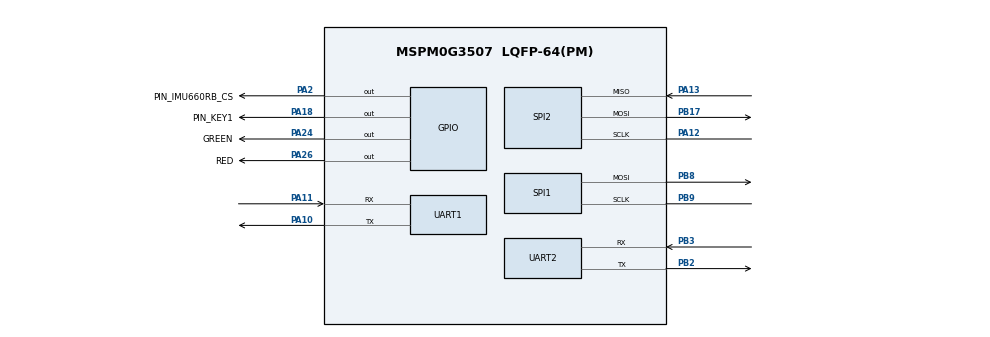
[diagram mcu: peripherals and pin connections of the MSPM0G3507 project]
/**
 * These arguments were used when this file was generated. They will be automatically applied on subsequent loads
 * via the GUI or CLI. Run CLI with '--help' for additional information on how to override these arguments.
 * @cliArgs --device "MSPM0G350X" --part "Default" --package "LQFP-64(PM)" --product "mspm0_sdk@2.02.00.05"
 * @v2CliArgs --device "MSPM0G3507" --package "LQFP-64(PM)" --product "mspm0_sdk@2.02.00.05"
 * @versions {"tool":"1.21.1+3772"}
 */

/**
 * Import the modules used in this configuration.
 */
const GPIO   = scripting.addModule("/ti/driverlib/GPIO", {}, false);
const GPIO1  = GPIO.addInstance();
const GPIO2  = GPIO.addInstance();
const GPIO3  = GPIO.addInstance();
const GPIO4  = GPIO.addInstance();
const I2C    = scripting.addModule("/ti/driverlib/I2C", {}, false);
const I2C1   = I2C.addInstance();
const SPI    = scripting.addModule("/ti/driverlib/SPI", {}, false);
const SPI1   = SPI.addInstance();
const SPI2   = SPI.addInstance();
const SYSCTL = scripting.addModule("/ti/driverlib/SYSCTL");
const UART   = scripting.addModule("/ti/driverlib/UART", {}, false);
const UART1  = UART.addInstance();
const UART2  = UART.addInstance();

/**
 * Write custom configuration values to the imported modules.
 */
const gate7  = system.clockTree["MFCLKGATE"];
gate7.enable = true;

GPIO1.$name                              = "LED1";
GPIO1.associatedPins.create(2);
GPIO1.associatedPins[0].internalResistor = "PULL_DOWN";
GPIO1.associatedPins[0].$name            = "RED";
GPIO1.associatedPins[0].assignedPin      = "26";
GPIO1.associatedPins[0].pin.$assign      = "PA26";
GPIO1.associatedPins[1].$name            = "GREEN";
GPIO1.associatedPins[1].pin.$assign      = "PA24";

const Board = scripting.addModule("/ti/driverlib/Board", {}, false);

GPIO2.$name                          = "SPI_LCD1";
GPIO2.associatedPins.create(4);
GPIO2.associatedPins[0].$name        = "RES";
GPIO2.associatedPins[0].assignedPort = "PORTB";
GPIO2.associatedPins[0].assignedPin  = "10";
GPIO2.associatedPins[1].$name        = "DC";
GPIO2.associatedPins[1].assignedPin  = "11";
GPIO2.associatedPins[1].assignedPort = "PORTB";
GPIO2.associatedPins[2].$name        = "CS";
GPIO2.associatedPins[2].assignedPort = "PORTB";
GPIO2.associatedPins[2].assignedPin  = "14";
GPIO2.associatedPins[3].$name        = "BLK";
GPIO2.associatedPins[3].assignedPort = "PORTB";
GPIO2.associatedPins[3].assignedPin  = "26";

GPIO3.$name                               = "GPIO_IMU660RB";
GPIO3.associatedPins.create(2);
GPIO3.associatedPins[0].$name             = "PIN_IMU660RB_CS";
GPIO3.associatedPins[0].pin.$assign       = "PA2";
GPIO3.associatedPins[1].$name             = "PIN_IMU660RB_INT1";
GPIO3.associatedPins[1].direction         = "INPUT";
GPIO3.associatedPins[1].interruptEn       = true;
GPIO3.associatedPins[1].interruptPriority = "3";
GPIO3.associatedPins[1].polarity          = "RISE";

GPIO4.$name                         = "GPIO_KEY";
GPIO4.associatedPins[0].$name       = "PIN_KEY1";
GPIO4.associatedPins[0].pin.$assign = "PA18";

I2C1.basicEnableController             = true;
I2C1.basicControllerStandardBusSpeed   = "Fast";
I2C1.$name                             = "I2C_OLED";
I2C1.sdaPinConfig.hideOutputInversion  = scripting.forceWrite(false);
I2C1.sdaPinConfig.onlyInternalResistor = scripting.forceWrite(false);
I2C1.sdaPinConfig.passedPeripheralType = scripting.forceWrite("Digital");
I2C1.sdaPinConfig.$name                = "ti_driverlib_gpio_GPIOPinGeneric2";
I2C1.sclPinConfig.hideOutputInversion  = scripting.forceWrite(false);
I2C1.sclPinConfig.onlyInternalResistor = scripting.forceWrite(false);
I2C1.sclPinConfig.passedPeripheralType = scripting.forceWrite("Digital");
I2C1.sclPinConfig.$name                = "ti_driverlib_gpio_GPIOPinGeneric3";

SPI1.$name                              = "SPI_LCD";
SPI1.peripheral.$assign                 = "SPI1";
SPI1.peripheral.sclkPin.$assign         = "PB9";
SPI1.peripheral.mosiPin.$assign         = "PB8";
SPI1.sclkPinConfig.direction            = scripting.forceWrite("OUTPUT");
SPI1.sclkPinConfig.onlyInternalResistor = scripting.forceWrite(false);
SPI1.sclkPinConfig.passedPeripheralType = scripting.forceWrite("Digital");
SPI1.sclkPinConfig.$name                = "ti_driverlib_gpio_GPIOPinGeneric8";
SPI1.mosiPinConfig.direction            = scripting.forceWrite("OUTPUT");
SPI1.mosiPinConfig.hideOutputInversion  = scripting.forceWrite(false);
SPI1.mosiPinConfig.onlyInternalResistor = scripting.forceWrite(false);
SPI1.mosiPinConfig.passedPeripheralType = scripting.forceWrite("Digital");
SPI1.mosiPinConfig.$name                = "ti_driverlib_gpio_GPIOPinGeneric9";
SPI1.misoPinConfig.onlyInternalResistor = scripting.forceWrite(false);
SPI1.misoPinConfig.passedPeripheralType = scripting.forceWrite("Digital");
SPI1.misoPinConfig.$name                = "ti_driverlib_gpio_GPIOPinGeneric10";
SPI1.cs0PinConfig.direction             = scripting.forceWrite("OUTPUT");
SPI1.cs0PinConfig.hideOutputInversion   = scripting.forceWrite(false);
SPI1.cs0PinConfig.onlyInternalResistor  = scripting.forceWrite(false);
SPI1.cs0PinConfig.passedPeripheralType  = scripting.forceWrite("Digital");
SPI1.cs0PinConfig.$name                 = "ti_driverlib_gpio_GPIOPinGeneric11";

SPI2.$name                              = "SPI_IMU660RB";
SPI2.frameFormat                        = "MOTO3";
SPI2.peripheral.$assign                 = "SPI0";
SPI2.peripheral.sclkPin.$assign         = "PA12";
SPI2.peripheral.mosiPin.$assign         = "PB17";
SPI2.peripheral.misoPin.$assign         = "PA13";
SPI2.sclkPinConfig.$name                = "ti_driverlib_gpio_GPIOPinGeneric6";
SPI2.sclkPinConfig.direction            = scripting.forceWrite("OUTPUT");
SPI2.sclkPinConfig.onlyInternalResistor = scripting.forceWrite(false);
SPI2.sclkPinConfig.passedPeripheralType = scripting.forceWrite("Digital");
SPI2.mosiPinConfig.$name                = "ti_driverlib_gpio_GPIOPinGeneric7";
SPI2.mosiPinConfig.direction            = scripting.forceWrite("OUTPUT");
SPI2.mosiPinConfig.hideOutputInversion  = scripting.forceWrite(false);
SPI2.mosiPinConfig.onlyInternalResistor = scripting.forceWrite(false);
SPI2.mosiPinConfig.passedPeripheralType = scripting.forceWrite("Digital");
SPI2.misoPinConfig.onlyInternalResistor = scripting.forceWrite(false);
SPI2.misoPinConfig.passedPeripheralType = scripting.forceWrite("Digital");
SPI2.misoPinConfig.$name                = "ti_driverlib_gpio_GPIOPinGeneric12";

SYSCTL.forceDefaultClkConfig = true;
SYSCTL.clockTreeEn           = true;

UART1.uartClkSrc                       = "MFCLK";
UART1.$name                            = "UART0";
UART1.enabledInterrupts                = ["RX","RX_TIMEOUT_ERROR"];
UART1.peripheral.rxPin.$assign         = "PA11";
UART1.peripheral.txPin.$assign         = "PA10";
UART1.txPinConfig.direction            = scripting.forceWrite("OUTPUT");
UART1.txPinConfig.hideOutputInversion  = scripting.forceWrite(false);
UART1.txPinConfig.onlyInternalResistor = scripting.forceWrite(false);
UART1.txPinConfig.passedPeripheralType = scripting.forceWrite("Digital");
UART1.txPinConfig.$name                = "ti_driverlib_gpio_GPIOPinGeneric0";
UART1.rxPinConfig.hideOutputInversion  = scripting.forceWrite(false);
UART1.rxPinConfig.onlyInternalResistor = scripting.forceWrite(false);
UART1.rxPinConfig.passedPeripheralType = scripting.forceWrite("Digital");
UART1.rxPinConfig.$name                = "ti_driverlib_gpio_GPIOPinGeneric1";

UART2.uartClkSrc                       = "MFCLK";
UART2.targetBaudRate                   = 115200;
UART2.$name                            = "UART3";
UART2.enabledInterrupts                = ["RX","RX_TIMEOUT_ERROR"];
UART2.peripheral.$assign               = "UART3";
UART2.peripheral.rxPin.$assign         = "PB3";
UART2.peripheral.txPin.$assign         = "PB2";
UART2.txPinConfig.direction            = scripting.forceWrite("OUTPUT");
UART2.txPinConfig.hideOutputInversion  = scripting.forceWrite(false);
UART2.txPinConfig.onlyInternalResistor = scripting.forceWrite(false);
UART2.txPinConfig.passedPeripheralType = scripting.forceWrite("Digital");
UART2.txPinConfig.$name                = "ti_driverlib_gpio_GPIOPinGeneric4";
UART2.rxPinConfig.hideOutputInversion  = scripting.forceWrite(false);
UART2.rxPinConfig.onlyInternalResistor = scripting.forceWrite(false);
UART2.rxPinConfig.passedPeripheralType = scripting.forceWrite("Digital");
UART2.rxPinConfig.$name                = "ti_driverlib_gpio_GPIOPinGeneric5";

/**
 * Pinmux solution for unlocked pins/peripherals. This ensures that minor changes to the automatic solver in a future
 * version of the tool will not impact the pinmux you originally saw.  These lines can be completely deleted in order to
 * re-solve from scratch.
 */
Board.peripheral.$suggestSolution            = "DEBUGSS";
Board.peripheral.swclkPin.$suggestSolution   = "PA20";
Board.peripheral.swdioPin.$suggestSolution   = "PA19";
GPIO2.associatedPins[0].pin.$suggestSolution = "PB10";
GPIO2.associatedPins[1].pin.$suggestSolution = "PB11";
GPIO2.associatedPins[2].pin.$suggestSolution = "PB14";
GPIO2.associatedPins[3].pin.$suggestSolution = "PB26";
GPIO3.associatedPins[1].pin.$suggestSolution = "PB13";
I2C1.peripheral.$suggestSolution             = "I2C0";
I2C1.peripheral.sdaPin.$suggestSolution      = "PA0";
I2C1.peripheral.sclPin.$suggestSolution      = "PA1";
SPI1.peripheral.misoPin.$suggestSolution     = "PA16";
SPI1.peripheral.cs0Pin.$suggestSolution      = "PB20";
UART1.peripheral.$suggestSolution            = "UART0";
